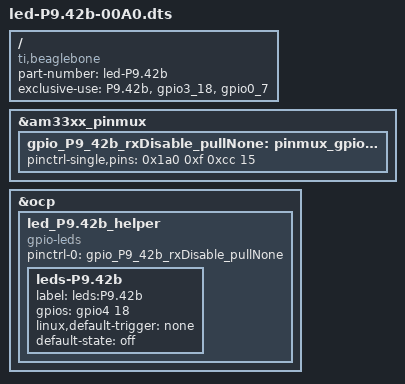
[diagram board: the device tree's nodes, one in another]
/*
* Easy gpio mux control of "P9.42b" ("gpio3_18", "gpio0_7")
*/
/dts-v1/;
/plugin/;

/ {
	compatible = "ti,beaglebone", "ti,beaglebone-black";

	/* identification */
	part-number = "led-P9.42b";
	/* version = "00A0"; */

	/* state the resources this cape uses */
	exclusive-use =
		/* the pin header uses */
		"P9.42b",

		/* the hardware IP uses */
		"gpio3_18", "gpio0_7";
	
	
	/* rxDisable_pullNone state */
	fragment@0 {
		target = <&am33xx_pinmux>;
		__overlay__ {
			gpio_P9_42b_rxDisable_pullNone: pinmux_gpio_P9.42b_rxDisable_pullNone {
				pinctrl-single,pins = <
					0x1a0 0xf	0xcc 15
				>;
			};
		};
	};

	fragment@1 {
		target = <&ocp>;
		__overlay__ {
			led_P9.42b_helper {
				compatible = "gpio-leds";
				pinctrl-names = "default";
				pinctrl-0 = <&gpio_P9_42b_rxDisable_pullNone>;
				
				leds-P9.42b {
					label = "leds:P9.42b";
					gpios = <&gpio4 18 0>;
					linux,default-trigger = "none";
					default-state = "off";
				};
			};
			
		};
	};

};
